# RZ/A1H register map
Vendor: Renesas
Registers are 32-bit, read-write, reset 0x0 unless marked. A register's access mark holds for its fields unless they carry their own. Offsets are from the block's base; lines under a group give offsets from that group; [hi:lo] are bit positions; {n}, {i} and the like mark numbered series; 'fields as' and 'values as' point back to an identical list; <NAME> marks a mode.

## Memory map
0x3FEFA000 SPIBSC0
0x3FEFB000 SPIBSC1
0x3FFFC000 BSC
0x3FFFF000 L2C
0xE8005000 ROMDEC
0xE8005800 ADC
{0xE8007000+0x800*n} SCIF{n} (n=0..7)
0xE800B000 SCIM0
0xE800B800 SCIM1
0xE800C800 RSPI0
0xE800D000 RSPI1
0xE800D800 RSPI2
0xE800E000 RSPI3
0xE800E800 RSPI4
0xE8010000 USB200
0xE8012000 SPDIF
0xE8014000 IRDA
0xE8017000 JCU
0xE8034000 MLB
0xE803A000 RSCAN0
0xE804C800 MMC
0xE8200000 DMAC
0xE8201000 INTC
0xE8203000 ETHER
0xE8205000 PFV0
0xE8205800 PFV1
0xE8207000 USB201
0xE8208000 SCUX
0xE820B000 SSIF0
0xE820B800 SSIF1
0xE820C000 SSIF2
0xE820C800 SSIF3
0xE820D000 SSIF4
0xE820D800 SSIF5
0xE8210000 CEU
0xFCFE0000 WDT
0xFCFE0010 CPG
0xFCFE1A00 INB
0xFCFE3004 GPIO
0xFCFE9000 LIN0
0xFCFE9800 LIN1
0xFCFEC000 OSTM0
0xFCFEC400 OSTM1
0xFCFEE000 RIIC0
0xFCFEE400 RIIC1
0xFCFEE800 RIIC2
0xFCFEEC00 RIIC3
0xFCFEF000 IEB
0xFCFF0000 MTU2
0xFCFF1000 RTC
0xFCFF4000 FLCTL
0xFCFF4800 SDG0
0xFCFF4A00 SDG1
0xFCFF4C00 SDG2
0xFCFF4E00 SDG3
0xFCFF5004 PWM
0xFCFF7400 VDC50
0xFCFF7A30 LVDS
0xFCFF9400 VDC51
0xFCFFA008 DVDEC1
0xFCFFA800 DISC0
0xFCFFB000 DISC1
0xFCFFB808 DVDEC0

## ADC
Base 0xE8005800
0x00 DRA 16-bit — ADDRA
  [15:0] D
0x02 DRB 16-bit — ADDRB
  [15:0] D
0x04 DRC 16-bit — ADDRC
  [15:0] D
0x06 DRD 16-bit — ADDRD
  [15:0] D
0x08 DRE 16-bit — ADDRE
  [15:0] D
0x0A DRF 16-bit — ADDRF
  [15:0] D
0x0C DRG 16-bit — ADDRG
  [15:0] D
0x0E DRH 16-bit — ADDRH
  [15:0] D
0x20 CMPHA 16-bit — ADCMPHA
0x22 CMPLA 16-bit — ADCMPLA
0x24 CMPHB 16-bit — ADCMPHB
0x26 CMPLB 16-bit — ADCMPLB
0x28 CMPHC 16-bit — ADCMPHC
0x2A CMPLC 16-bit — ADCMPLC
0x2C CMPHD 16-bit — ADCMPHD
0x2E CMPLD 16-bit — ADCMPLD
0x30 CMPHE 16-bit — ADCMPHE
0x32 CMPLE 16-bit — ADCMPLE
0x34 CMPHF 16-bit — ADCMPHF
0x36 CMPLF 16-bit — ADCMPLF
0x38 CMPHG 16-bit — ADCMPHG
0x3A CMPLG 16-bit — ADCMPLG
0x3C CMPHH 16-bit — ADCMPHH
0x3E CMPLH 16-bit — ADCMPLH
0x60 CSR 16-bit — ADCSR
0x62 CMPER 16-bit — ADCMPER
0x64 CMPSR 16-bit — ADCMPSR

## BSC
Base 0x3FFFC000
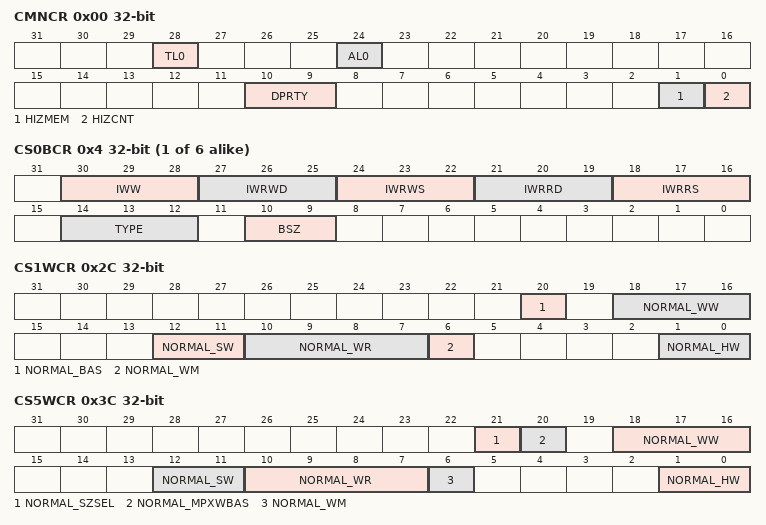
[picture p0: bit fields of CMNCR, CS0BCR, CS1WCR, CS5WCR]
0x00 CMNCR
  [28] TL0, [24] AL0, [10:9] DPRTY, [1] HIZMEM, [0] HIZCNT
{0x4+4i} CS{i}BCR (i=0..5)
  [30:28] IWW, [27:25] IWRWD, [24:22] IWRWS, [21:19] IWRRD, [18:16] IWRRS, [14:12] TYPE, [10:9] BSZ
0x28 CS0WCR
  [20] NORMAL_BAS, [21:20] BROM_ASY_BST, [17:16] BROM_ASY_BW, [17:16] BROM_SY_BW, [12:11] NORMAL_SW, [10:7] NORMAL_WR, [10:7] BROM_ASY_W, [10:7] BROM_SY_W, [6] NORMAL_WM, [6] BROM_ASY_WM, [6] BROM_SY_WM, [1:0] NORMAL_HW
0x2C CS1WCR
  [20] NORMAL_BAS, [18:16] NORMAL_WW, [12:11] NORMAL_SW, [10:7] NORMAL_WR, [6] NORMAL_WM, [1:0] NORMAL_HW
0x30 CS2WCR
  [20] NORMAL_BAS, [10:7] NORMAL_WR, [8:7] SDRAM_A2CL, [6] NORMAL_WM
0x34 CS3WCR
  [20] NORMAL_BAS, [14:13] SDRAM_WTRP, [11:10] SDRAM_WTRCD, [10:7] NORMAL_WR, [8:7] SDRAM_A3CL, [6] NORMAL_WM, [4:3] SDRAM_TRWL, [1:0] SDRAM_WTRC
0x38 CS4WCR
  [20] NORMAL_BAS, [21:20] BROM_ASY_BST, [18:16] NORMAL_WW, [17:16] BROM_ASY_BW, [12:11] NORMAL_SW, [12:11] BROM_ASY_SW, [10:7] NORMAL_WR, [10:7] BROM_ASY_W, [6] NORMAL_WM, [6] BROM_ASY_WM, [1:0] NORMAL_HW, [1:0] BROM_ASY_HW
0x3C CS5WCR
  [21] NORMAL_SZSEL, [20] NORMAL_MPXWBAS, [18:16] NORMAL_WW, [12:11] NORMAL_SW, [10:7] NORMAL_WR, [6] NORMAL_WM, [1:0] NORMAL_HW
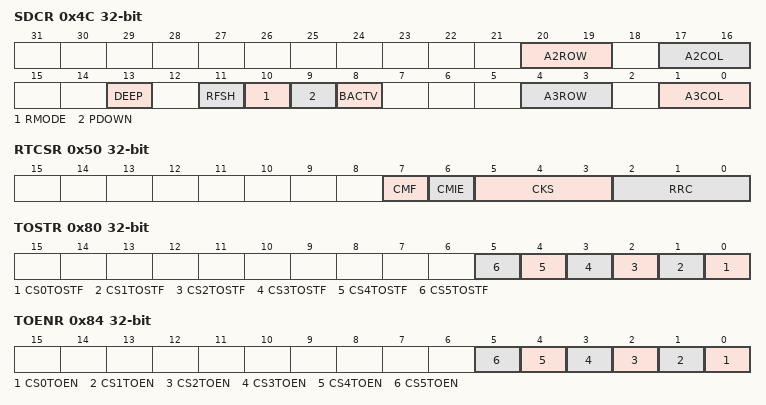
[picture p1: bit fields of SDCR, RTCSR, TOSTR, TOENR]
0x4C SDCR
  [20:19] A2ROW, [17:16] A2COL, [13] DEEP, [11] RFSH, [10] RMODE, [9] PDOWN, [8] BACTV, [4:3] A3ROW, [1:0] A3COL
0x50 RTCSR
  [7] CMF, [6] CMIE, [5:3] CKS, [2:0] RRC
0x54 RTCNT
  [31:0] D
0x58 RTCOR
  [31:0] D
{0x60+4i} TOSCOR{i} (i=0..5)
  [15:0] D
0x80 TOSTR
  [n] CS{n}TOSTF (n=0..5)
0x84 TOENR
  [n] CS{n}TOEN (n=0..5)

## CEU
Base 0xE8210000
0x00 CAPSR
0x04 CAPCR
0x08 CAMCR
0x0C CMCYR
0x10 CAMOR_A
0x14 CAPWR_A
0x18 CAIFR
0x28 CRCNTR
0x2C CRCMPR
0x30 CFLCR_A
0x34 CFSZR_A
0x38 CDWDR_A
0x3C CDAYR_A
0x40 CDACR_A
0x44 CDBYR_A
0x48 CDBCR_A
0x4C CBDSR_A
0x5C CFWCR
0x60 CLFCR_A
0x64 CDOCR_A
0x70 CEIER
0x74 CETCR
0x7C CSTSR
0x84 CDSSR
0x90 CDAYR2_A
0x94 CDACR2_A
0x98 CDBYR2_A
0x9C CDBCR2_A
0x1010 CAMOR_B
0x1014 CAPWR_B
0x1030 CFLCR_B
0x1034 CFSZR_B
0x1038 CDWDR_B
0x103C CDAYR_B
0x1040 CDACR_B
0x1044 CDBYR_B
0x1048 CDBCR_B
0x104C CBDSR_B
0x1060 CLFCR_B
0x1064 CDOCR_B
0x1090 CDAYR2_B
0x1094 CDACR2_B
0x1098 CDBYR2_B
0x109C CDBCR2_B
0x2010 CAMOR_M
0x2014 CAPWR_M
0x2030 CFLCR_M
0x2034 CFSZR_M
0x2038 CDWDR_M
0x203C CDAYR_M
0x2040 CDACR_M
0x2044 CDBYR_M
0x2048 CDBCR_M
0x204C CBDSR_M
0x2060 CLFCR_M
0x2064 CDOCR_M
0x2090 CDAYR2_M
0x2094 CDACR2_M
0x2098 CDBYR2_M
0x209C CDBCR2_M
